# MM32F013x register map
File version: 1.01
CPU: CM0 r0p0, little endian, no MPU, no FPU, 2 interrupt priority bits
Registers are 32-bit, read-write, reset 0x0 unless marked. A register's access mark holds for its fields unless they carry their own. Offsets are from the block's base; [hi:lo] are bit positions; {n}, {i} and the like mark numbered series.

## FLASH
Base 0x40022000
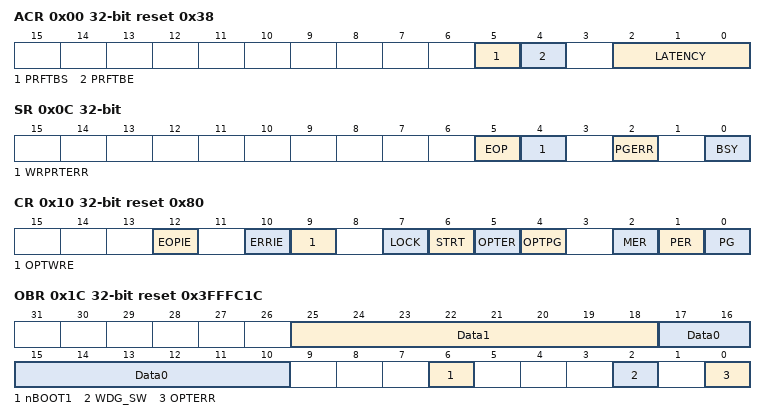
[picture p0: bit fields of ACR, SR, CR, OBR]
0x00 ACR reset 0x38 — Flash access control register
  [5] PRFTBS — Prefetch buffer status
  [4] PRFTBE — Prefetch enable
  [2:0] LATENCY
0x04 KEYR wo — Flash key
  [31:0] FKEYR
0x08 OPTKEYR wo — Option byte key
0x0C SR — Flash status register
  [5] EOP — End of operation
  [4] WRPRTERR — Write protection error
  [2] PGERR — Programming error
  [0] BSY — Busy
0x10 CR reset 0x80 — Flash control register
  [12] EOPIE — End of operation interrupt enable
  [10] ERRIE — Error interrupt enable
  [9] OPTWRE — Option byte write enable
  [7] LOCK
  [6] STRT — Start
  [5] OPTER — Option byte erase
  [4] OPTPG — Option byte programming
  [2] MER — Mass erase
  [1] PER — Page erase
  [0] PG — Programming
0x14 AR wo — Flash address register
  [31:0] FAR — Flash Address
0x1C OBR ro reset 0x3FFFC1C — Option byte register
  [25:18] Data1
  [17:10] Data0
  [6] nBOOT1
  [2] WDG_SW
  [0] OPTERR — Option byte error
0x20 WRPR ro reset 0xFFFFFFFF — Write protect register
  [31:0] WRP — Write protect

## GPIOA — General purpose I/O
Base 0x48000000
Same registers: GPIOB 0x48000400, GPIOC 0x48000800, GPIOD 0x48000C00
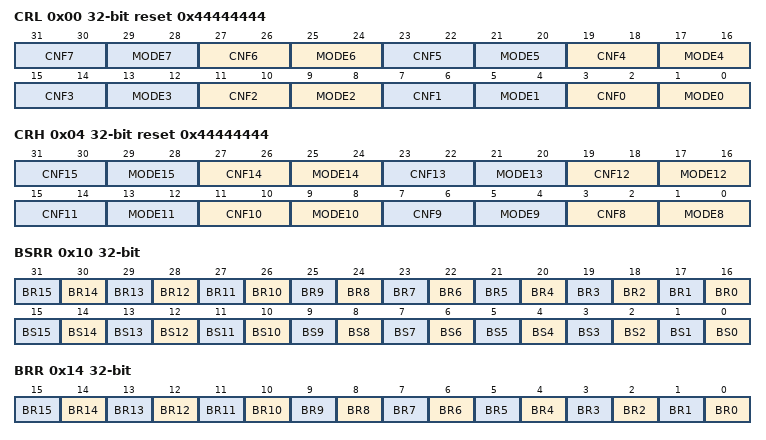
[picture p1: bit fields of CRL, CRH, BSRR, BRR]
0x00 CRL reset 0x44444444 — configuration low register
  [4n+3:4n+2] CNF{n} (n=0..7) — Port {n} configuration bits
  [4n+1:4n] MODE{n} (n=0..7) — Port {n} mode bits
0x04 CRH reset 0x44444444 — configuration high register
  [4n-29:4n-30] CNF{n} (n=8..15) — Port {n} configuration bits
  [4n-31:4n-32] MODE{n} (n=8..15) — Port {n} mode bits
0x08 IDR ro — input data register
  [15:0] IDR — Port input data
0x0C ODR — output data register
  [15:0] ODR — Port output data
0x10 BSRR wo — bit set/reset register
  [n+16] BR{n} (n=0..15) — Port x Reset bit {n}
  [n] BS{n} (n=0..15) — Port x Set bit {n}
0x14 BRR wo — bit reset register
  [n] BR{n} (n=0..15) — Port x Reset bit {n}
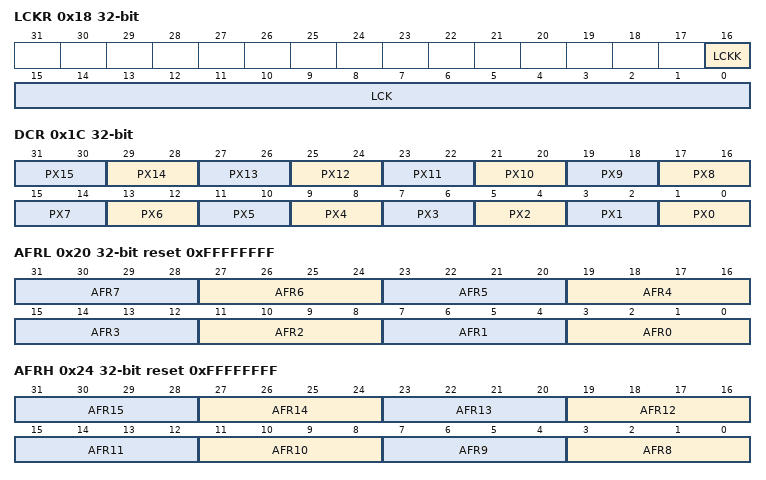
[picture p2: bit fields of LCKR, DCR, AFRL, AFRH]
0x18 LCKR — Port configuration lock register
  [16] LCKK — Lock key
  [15:0] LCK — Port x Lock bit y
0x1C DCR — Port output open drain control register
  [2n+1:2n] PX{n} (n=0..15)
0x20 AFRL reset 0xFFFFFFFF — Port Multiplexing Function Low Register
  [4n+3:4n] AFR{n} (n=0..7) — Multiplexing function selection for bit {n} of portx
0x24 AFRH reset 0xFFFFFFFF — Port Multiplexing Function High Register
  [4n-29:4n-32] AFR{n} (n=8..15) — Multiplexing function selection for bit {n} of portx

## HWDIV — Hardware divider
Base 0x40030000
0x00 DVDR — Dividend register
  [31:0] DIVIDEND — Dividend data
0x04 DVSR reset 0x1 — Divisor register
  [31:0] DIVISOR — Divisor data
0x08 QUOTR ro — Quotient register
  [31:0] QUOTIENT — Quotient data
0x0C RMDR ro — Remainder register
  [31:0] REMAINDER — Remainder data
0x10 SR ro — status register
  [0] OVF — Overflow flag
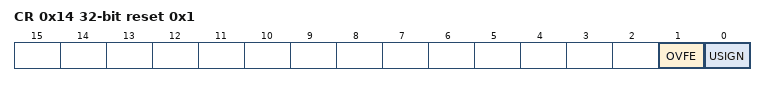
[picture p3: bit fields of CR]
0x14 CR reset 0x1 — control register
  [1] OVFE — Overflow interrupt enable
  [0] USIGN — unsigned enable

## IWDG — Independent watchdog
Base 0x40003000
0x00 KR wo — Key register
  [15:0] KEY — Key value
0x04 PR — Prescaler register
  [2:0] PR — Prescaler divider
0x08 RLR reset 0xFFF — Reload register
  [11:0] RL — Watchdog counter reload value
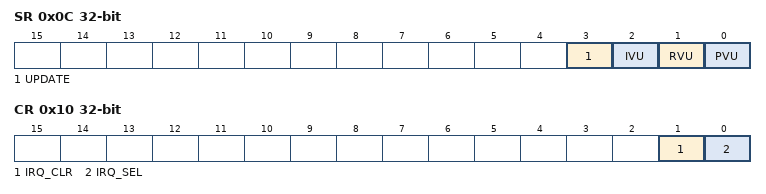
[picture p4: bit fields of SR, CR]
0x0C SR ro — Status register
  [3] UPDATE — Watchdog reload value update flag
  [2] IVU — Watchdog interrupt generate value update
  [1] RVU — Watchdog counter reload value update
  [0] PVU — Watchdog prescaler value update
0x10 CR — Control register
  [1] IRQ_CLR — Interruput clear
  [0] IRQ_SEL — Interruput select
0x14 IGEN — Interruput generate value register
  [11:0] IGEN — Watchdog Interrupt Generate value

## PWR — Power control
Base 0x40007000
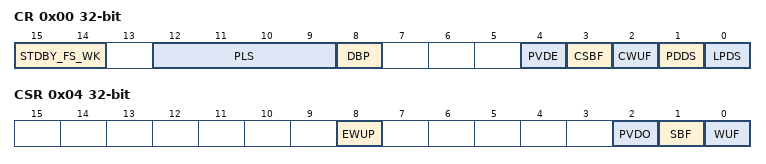
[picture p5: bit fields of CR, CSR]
0x00 CR
  [15:14] STDBY_FS_WK — Quickly wake-up standby mode selection
  [12:9] PLS — PVD level selection
  [8] DBP — domain write protection
  [4] PVDE — Power voltage detector enable
  [3] CSBF — Clear standby flag
  [2] CWUF — Clear wakeup flag
  [1] PDDS — Power down deepsleep
  [0] LPDS — Low power deepsleep
0x04 CSR
  [8] EWUP — Enable WKUP pin
  [2] PVDO — PVD output
  [1] SBF — Standby flag
  [0] WUF — Wakeup flag
